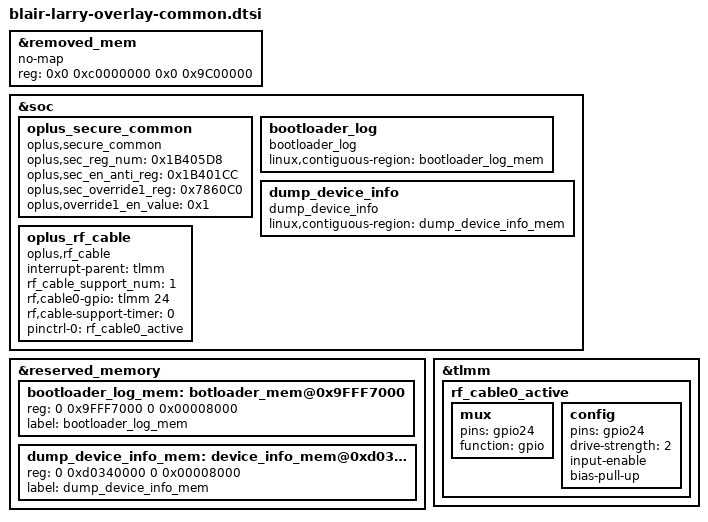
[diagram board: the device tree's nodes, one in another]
#include "../qcom/blair-mtp-nopmi-overlay.dts"

/* DTBO: Platform common generic overlay */
#include "oplus_fp/oplus_fp_22821.dtsi"
#include "tp/larry-oplus-tp-22821.dtsi"
#include "oplus_camera_pmic/wl2868c.dtsi"
#include "oplus_chg/oplus-chg-22821.dtsi"

//#ifdef OPLUS_FEATURE_SECURITY_COMMON
// expand tz mem
&removed_mem {
	no-map;
        reg = <0x0 0xc0000000 0x0 0x9C00000>;
};
//#endif /*OPLUS_FEATURE_SECURITY_COMMON*/

&soc{
    //#ifdef OPLUS_FEATURE_SECURITY_COMMON
    /* 2023/10/13 add for oplus secure */
    oplus_secure_common {
        compatible = "oplus,secure_common";
        oplus,sec_reg_num = <0x1B405D8>;
        oplus,sec_en_anti_reg = <0x1B401CC>;
        oplus,sec_override1_reg = <0x7860C0>;
        oplus,override1_en_value = <0x1>;
    };
    //#endif /*OPLUS_FEATURE_SECURITY_COMMON*/
    bootloader_log {
         compatible = "bootloader_log";
         linux,contiguous-region = <&bootloader_log_mem>;
     };
    dump_device_info {
         compatible = "dump_device_info";
         linux,contiguous-region = <&dump_device_info_mem>;
    };
};
&reserved_memory {
        /*
        This size is from
        boot_images/boot/QcomPkg/SocPkg/StraitPkg/LAA/uefiplat.cfg
        0x9FFF7000, 0x00008000, "Log Buffer",        AddMem, SYS_MEM, SYS_MEM_CAP, RtData, WRITE_BACK_XN
        so we reserve this for bootloader log
        */
        bootloader_log_mem: botloader_mem@0x9FFF7000 {
                reg = <0 0x9FFF7000 0 0x00008000>;
                label = "bootloader_log_mem";
        };

        dump_device_info_mem: device_info_mem@0xd0340000 {
                reg = <0 0xd0340000 0 0x00008000>;
                label = "dump_device_info_mem";
        };
};

//#ifdef OPLUS_FEATURE_RF_CABLE_DETECT
&tlmm {
	rf_cable0_active: rf_cable0_active {
		mux {
			pins = "gpio24";
			function = "gpio";
		};
		config {
			pins = "gpio24";
			drive-strength = <2>;
			input-enable;
			bias-pull-up;
		};
	};
};

&soc {
	oplus_rf_cable {
		compatible = "oplus,rf_cable";
		interrupt-parent = <&tlmm>;
		rf_cable_support_num = <1>;
		rf,cable0-gpio = <&tlmm 24 0>;
		rf,cable-support-timer = <0>;
		pinctrl-names = "rf_cable_active";
		pinctrl-0 = <&rf_cable0_active>;
	};
};
//#endif /* OPLUS_FEATURE_RF_CABLE_DETECT */
